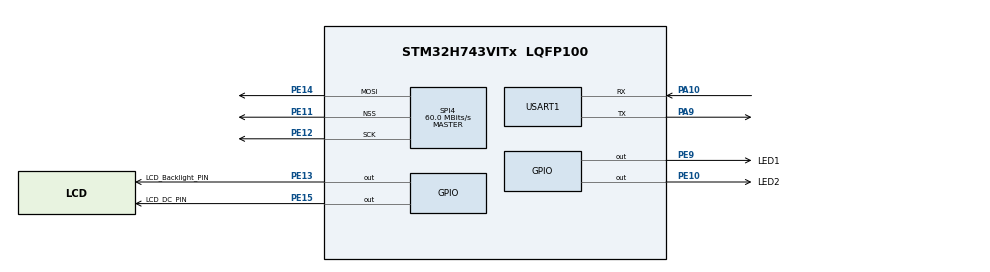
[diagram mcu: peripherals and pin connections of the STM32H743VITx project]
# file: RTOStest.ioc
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CORTEX_M7.default_mode_Activation=1
FREERTOS.Tasks01=defaultTask,24,128,StartDefaultTask,Default,NULL,Dynamic,NULL,NULL
FREERTOS.configRECORD_STACK_HIGH_ADDRESS=1
FREERTOS.configTOTAL_HEAP_SIZE=65536
FREERTOS.configUSE_NEWLIB_REENTRANT=0
Mcu.Family=STM32H7
Mcu.Name=STM32H743VITx
Mcu.Package=LQFP100
Mcu.UserConstants=LCD_SPI,$$_SPI4_IP_HANDLE_$$
NVIC.PriorityGroup=NVIC_PRIORITYGROUP_4
NVIC.TIM6_DAC_IRQn=true\:15\:0\:false\:false\:true\:false\:false\:true\:true
NVIC.TimeBase=TIM6_DAC_IRQn
NVIC.TimeBaseIP=TIM6
PA10.Mode=Asynchronous
PA10.Signal=USART1_RX
PA9.Mode=Asynchronous
PA9.Signal=USART1_TX
PC14-OSC32_IN\ (OSC32_IN).Mode=LSE-External-Oscillator
PC14-OSC32_IN\ (OSC32_IN).Signal=RCC_OSC32_IN
PC15-OSC32_OUT\ (OSC32_OUT).Mode=LSE-External-Oscillator
PC15-OSC32_OUT\ (OSC32_OUT).Signal=RCC_OSC32_OUT
PE10.GPIO_Label=LED2
PE10.Signal=GPIO_Output
PE11.GPIO_Mode=GPIO_MODE_AF_PP
PE11.GPIO_PuPd=GPIO_NOPULL
PE11.GPIO_Speed=GPIO_SPEED_FREQ_VERY_HIGH
PE11.Mode=NSS_Signal_Hard_Output
PE11.Signal=SPI4_NSS
PE12.GPIO_Speed=GPIO_SPEED_FREQ_VERY_HIGH
PE12.Mode=TX_Only_Simplex_Unidirect_Master
PE12.Signal=SPI4_SCK
PE13.GPIO_Label=LCD_Backlight_PIN
PE13.Signal=GPIO_Output
PE14.GPIO_Speed=GPIO_SPEED_FREQ_VERY_HIGH
PE14.Mode=TX_Only_Simplex_Unidirect_Master
PE14.Signal=SPI4_MOSI
PE15.GPIO_Label=LCD_DC_PIN
PE15.Signal=GPIO_Output
PE9.GPIO_Label=LED1
PE9.Signal=GPIO_Output
PH0-OSC_IN\ (PH0).Mode=HSE-External-Oscillator
PH0-OSC_IN\ (PH0).Signal=RCC_OSC_IN
PH1-OSC_OUT\ (PH1).Mode=HSE-External-Oscillator
PH1-OSC_OUT\ (PH1).Signal=RCC_OSC_OUT
ProjectManager.HeapSize=0x200
ProjectManager.StackSize=0x400
ProjectManager.TargetToolchain=MDK-ARM V5.32
RCC.ADCFreq_Value=50390625
RCC.APB1Freq_Value=120000000
RCC.APB2Freq_Value=120000000
RCC.APB3Freq_Value=120000000
RCC.APB4Freq_Value=120000000
RCC.CortexFreq_Value=480000000
RCC.D1PPRE=RCC_APB3_DIV2
RCC.D2PPRE1=RCC_APB1_DIV2
RCC.D2PPRE2=RCC_APB2_DIV2
RCC.D3PPRE=RCC_APB4_DIV2
RCC.DIVM1=5
RCC.DIVN1=192
RCC.HCLKFreq_Value=240000000
RCC.HPRE=RCC_HCLK_DIV2
RCC.PLL2FRACN=0
RCC.PLL3FRACN=0
RCC.PLLFRACN=0
RCC.PLLSourceVirtual=RCC_PLLSOURCE_HSE
RCC.RTCClockSelection=RCC_RTCCLKSOURCE_LSE
RCC.SYSCLKFreq_VALUE=480000000
RCC.SYSCLKSource=RCC_SYSCLKSOURCE_PLLCLK
RCC.USBFreq_Value=480000000
SPI4.CalculateBaudRate=60.0 MBits/s
SPI4.DataSize=SPI_DATASIZE_8BIT
SPI4.Direction=SPI_DIRECTION_2LINES_TXONLY
SPI4.FifoThreshold=SPI_FIFO_THRESHOLD_02DATA
SPI4.Mode=SPI_MODE_MASTER
SPI4.TIMode=SPI_TIMODE_DISABLE
SPI4.VirtualNSS=VM_NSSHARD
SPI4.VirtualType=VM_MASTER
USART1.VirtualMode-Asynchronous=VM_ASYNC
VP_FREERTOS_VS_CMSIS_V2.Mode=CMSIS_V2
VP_MEMORYMAP_VS_MEMORYMAP.Mode=CurAppReg
VP_RTC_VS_RTC_Activate.Mode=RTC_Enabled
VP_RTC_VS_RTC_Calendar.Mode=RTC_Calendar
VP_SYS_VS_tim6.Mode=TIM6
board=custom

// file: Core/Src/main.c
/* USER CODE BEGIN Header */
/**
  ******************************************************************************
  * @file           : main.c
  * @brief          : Main program body
  ******************************************************************************
  * @attention
  *
  * Copyright (c) 2026 STMicroelectronics.
  * All rights reserved.
  *
  * This software is licensed under terms that can be found in the LICENSE file
  * in the root directory of this software component.
  * If no LICENSE file comes with this software, it is provided AS-IS.
  *
  ******************************************************************************
  */
/* USER CODE END Header */
#include "main.h"
#include "FreeRTOS.h"
#include "cmsis_os2.h"
#include "rtc.h"
#include "spi.h"
#include "usart.h"
#include "gpio.h"

/* USER CODE BEGIN Includes */
#include <stdio.h>
#include "bsp_rtc.h"
/* USER CODE END Includes */

void SystemClock_Config(void);
static void MPU_Config(void);
void MX_FREERTOS_Init(void);

int main(void)
{

  /* MPU Configuration--------------------------------------------------------*/
  MPU_Config();

  /* MCU Configuration--------------------------------------------------------*/

  /* Reset of all peripherals, Initializes the Flash interface and the Systick. */
  HAL_Init();

  /* Configure the system clock */
  SystemClock_Config();

  /* Initialize all configured peripherals */
  MX_GPIO_Init();
  MX_USART1_UART_Init();
  MX_SPI4_Init();
  MX_RTC_Init();

  /* Init scheduler */
  osKernelInitialize();  /* Call init function for freertos objects (in cmsis_os2.c) */
  MX_FREERTOS_Init();

  /* Start scheduler */
  osKernelStart();

  /* We should never get here as control is now taken by the scheduler */

  /* Infinite loop */
  while (1)
  {

  }
}

void SystemClock_Config(void)
{
  RCC_OscInitTypeDef RCC_OscInitStruct = {0};
  RCC_ClkInitTypeDef RCC_ClkInitStruct = {0};

  /** Supply configuration update enable
  */
  HAL_PWREx_ConfigSupply(PWR_LDO_SUPPLY);

  /** Configure the main internal regulator output voltage
  */
  __HAL_PWR_VOLTAGESCALING_CONFIG(PWR_REGULATOR_VOLTAGE_SCALE0);

  while(!__HAL_PWR_GET_FLAG(PWR_FLAG_VOSRDY)) {}

  /** Configure LSE Drive Capability
  */
  HAL_PWR_EnableBkUpAccess();
  __HAL_RCC_LSEDRIVE_CONFIG(RCC_LSEDRIVE_LOW);

  /** Initializes the RCC Oscillators according to the specified parameters
  * in the RCC_OscInitTypeDef structure.
  */
  RCC_OscInitStruct.OscillatorType = RCC_OSCILLATORTYPE_HSE|RCC_OSCILLATORTYPE_LSE;
  RCC_OscInitStruct.HSEState = RCC_HSE_ON;
  RCC_OscInitStruct.LSEState = RCC_LSE_ON;
  RCC_OscInitStruct.PLL.PLLState = RCC_PLL_ON;
  RCC_OscInitStruct.PLL.PLLSource = RCC_PLLSOURCE_HSE;
  RCC_OscInitStruct.PLL.PLLM = 5;
  RCC_OscInitStruct.PLL.PLLN = 192;
  RCC_OscInitStruct.PLL.PLLP = 2;
  RCC_OscInitStruct.PLL.PLLQ = 2;
  RCC_OscInitStruct.PLL.PLLR = 2;
  RCC_OscInitStruct.PLL.PLLRGE = RCC_PLL1VCIRANGE_2;
  RCC_OscInitStruct.PLL.PLLVCOSEL = RCC_PLL1VCOWIDE;
  RCC_OscInitStruct.PLL.PLLFRACN = 0;
  if (HAL_RCC_OscConfig(&RCC_OscInitStruct) != HAL_OK)
  {
    Error_Handler();
  }

  /** Initializes the CPU, AHB and APB buses clocks
  */
  RCC_ClkInitStruct.ClockType = RCC_CLOCKTYPE_HCLK|RCC_CLOCKTYPE_SYSCLK
                              |RCC_CLOCKTYPE_PCLK1|RCC_CLOCKTYPE_PCLK2
                              |RCC_CLOCKTYPE_D3PCLK1|RCC_CLOCKTYPE_D1PCLK1;
  RCC_ClkInitStruct.SYSCLKSource = RCC_SYSCLKSOURCE_PLLCLK;
  RCC_ClkInitStruct.SYSCLKDivider = RCC_SYSCLK_DIV1;
  RCC_ClkInitStruct.AHBCLKDivider = RCC_HCLK_DIV2;
  RCC_ClkInitStruct.APB3CLKDivider = RCC_APB3_DIV2;
  RCC_ClkInitStruct.APB1CLKDivider = RCC_APB1_DIV2;
  RCC_ClkInitStruct.APB2CLKDivider = RCC_APB2_DIV2;
  RCC_ClkInitStruct.APB4CLKDivider = RCC_APB4_DIV2;

  if (HAL_RCC_ClockConfig(&RCC_ClkInitStruct, FLASH_LATENCY_4) != HAL_OK)
  {
    Error_Handler();
  }
}

 /* MPU Configuration */

void MPU_Config(void)
{
  MPU_Region_InitTypeDef MPU_InitStruct = {0};

  /* Disables the MPU */
  HAL_MPU_Disable();

  /** Initializes and configures the Region and the memory to be protected
  */
  MPU_InitStruct.Enable = MPU_REGION_ENABLE;
  MPU_InitStruct.Number = MPU_REGION_NUMBER0;
  MPU_InitStruct.BaseAddress = 0x0;
  MPU_InitStruct.Size = MPU_REGION_SIZE_4GB;
  MPU_InitStruct.SubRegionDisable = 0x87;
  MPU_InitStruct.TypeExtField = MPU_TEX_LEVEL0;
  MPU_InitStruct.AccessPermission = MPU_REGION_NO_ACCESS;
  MPU_InitStruct.DisableExec = MPU_INSTRUCTION_ACCESS_DISABLE;
  MPU_InitStruct.IsShareable = MPU_ACCESS_SHAREABLE;
  MPU_InitStruct.IsCacheable = MPU_ACCESS_NOT_CACHEABLE;
  MPU_InitStruct.IsBufferable = MPU_ACCESS_NOT_BUFFERABLE;

  HAL_MPU_ConfigRegion(&MPU_InitStruct);
  /* Enables the MPU */
  HAL_MPU_Enable(MPU_PRIVILEGED_DEFAULT);

}

void HAL_TIM_PeriodElapsedCallback(TIM_HandleTypeDef *htim)
{
  if (htim->Instance == TIM6)
  {
    HAL_IncTick();
  }
}

void Error_Handler(void)
{
  __disable_irq();
  while (1)
  {
  }
}

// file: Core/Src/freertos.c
/* USER CODE BEGIN Header */
/**
  ******************************************************************************
  * File Name          : freertos.c
  * Description        : Code for freertos applications
  ******************************************************************************
  * @attention
  *
  * Copyright (c) 2026 STMicroelectronics.
  * All rights reserved.
  *
  * This software is licensed under terms that can be found in the LICENSE file
  * in the root directory of this software component.
  * If no LICENSE file comes with this software, it is provided AS-IS.
  *
  ******************************************************************************
  */
/* USER CODE END Header */

#include "FreeRTOS.h"
#include "task.h"
#include "main.h"
#include "FreeRTOS.h"
#include "cmsis_os2.h"

/* USER CODE BEGIN Includes */
#include "app_tasks.h"
/* USER CODE END Includes */

/* Definitions for defaultTask */
osThreadId_t defaultTaskHandle;
const osThreadAttr_t defaultTask_attributes = {
  .name = "defaultTask",
  .stack_size = 128 * 4,
  .priority = (osPriority_t) osPriorityNormal,
};

void StartDefaultTask(void *argument);

void MX_FREERTOS_Init(void); /* (MISRA C 2004 rule 8.1) */

void MX_FREERTOS_Init(void) {
  /* USER CODE BEGIN Init */
  xTaskCreate(vLedTask,     "LED", 128,  NULL, 1, NULL);
  xTaskCreate(vDisplayTask, "LCD", 2048, NULL, 1, NULL);
  /* USER CODE END Init */

  /* Create the thread(s) */
  /* creation of defaultTask */
  defaultTaskHandle = osThreadNew(StartDefaultTask, NULL, &defaultTask_attributes);

}

void StartDefaultTask(void *argument)
{
  for(;;)
  {
    osDelay(1);
  }
}
